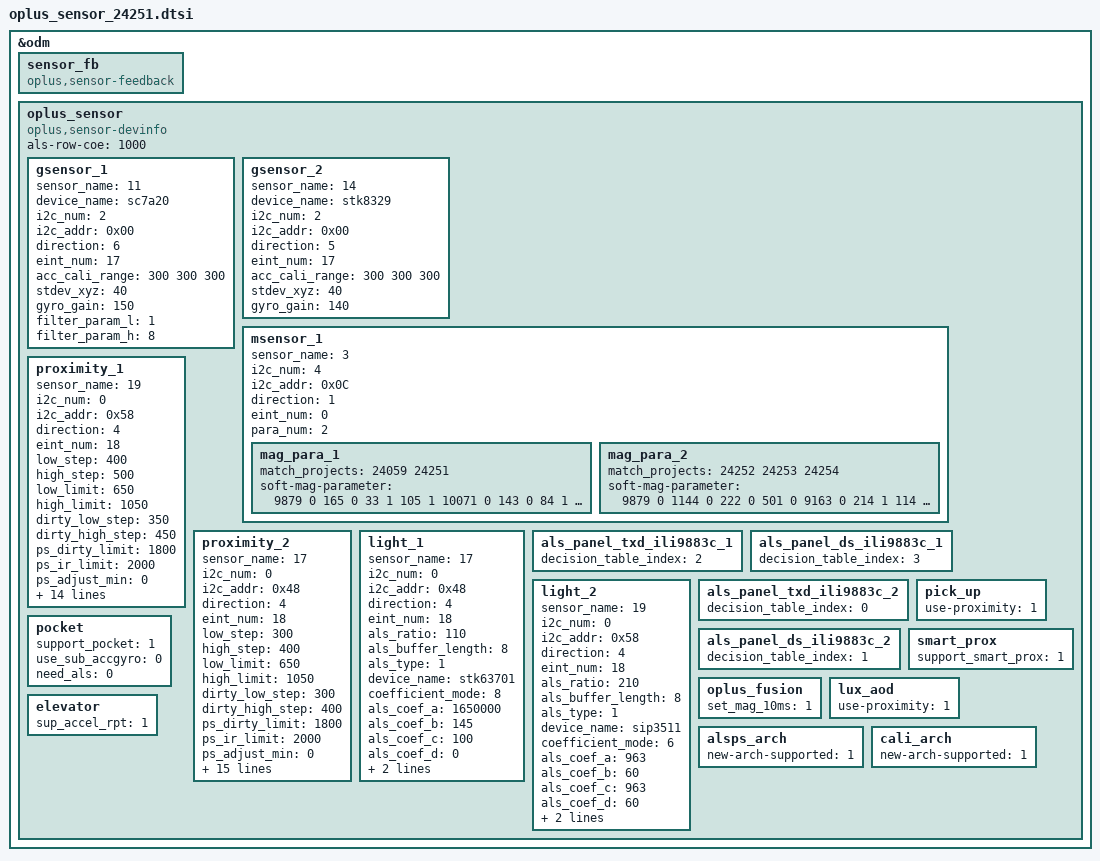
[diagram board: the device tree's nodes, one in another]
&odm {
	sensor_fb: sensor_fb {
		compatible = "oplus,sensor-feedback";
	};
	oplus_sensor:oplus_sensor {
		compatible = "oplus,sensor-devinfo";
		als-row-coe = <1000>;
		/* sensor start */
		/*
		enum {
			LIS3DH,
			LSM6DS3,
			BMI160,
			LIS2HH12,
			LSM6DSM,
			BMI2XY,
			LSM6DSO,
			ICM4X6XX,
			ICM4263X,
			ICM4N607,
			BMI22X,
			SC7A20,
			MC34X9,
			BMA4XY,
			STK8329,
			BMI3XY,
		};
		*/
		gsensor_1: gsensor_1 {
			status = "okay";
			sensor_name = <11>;//SC7A20
			device_name = "sc7a20";
			i2c_num = <2>;
			i2c_addr = <0x00>;
			direction = <6>;
			eint_num = <17>;
			acc_cali_range= <300 300 300>;
			stdev_xyz = <40>;
			gyro_gain = <150>;
			filter_param_l = <1>;
			filter_param_h = <8>;
		};
		gsensor_2: gsensor_2 {
			status = "okay";
			sensor_name = <14>;//STK8329
			device_name = "stk8329";
			i2c_num = <2>;
			i2c_addr = <0x00>;
			direction = <5>;
			eint_num = <17>;
			acc_cali_range= <300 300 300>;
			stdev_xyz = <40>;
			gyro_gain = <140>;
		};
		/*
		enum {
			AKM09911,
			MMC3530,
			MMC5603,
			MXG4300,
			AKM09918,
		};
		*/
		msensor_1: msensor_1 {
			status = "okay";
			sensor_name = <3>;//MXG4300
			i2c_num = <4>;
			i2c_addr = <0x0C>;
			direction = <1>;
			eint_num = <0>;
			para_num = <2>;
			mag_para_1 {
				match_projects = <24059 24251>;
				soft-mag-parameter = <9879 0 165 0 33 1 105 1 10071 0 143 0 84 1 102 1 10746 0>;
			};
			mag_para_2 {
				match_projects = <24252 24253 24254>;   // NFC
				soft-mag-parameter = <9879 0 1144 0 222 0 501 0 9163 0 214 1 114 1 236 1 10777 0>;
			};
		};
		/*
		enum {
			TMD2725,
			APSD9922,
			STK3335,
			STK3331,
			STK2232,
			TCS3701,
			STK32600,
			STK33502,
			MN78911,
			TCS3720,
			SIP3515,
			STK3329,
			LTR569,
			SIP3510,
		};
		*/
		proximity_1: proximity_1 {
			status = "okay";
			sensor_name = <19>; //SIP3511
			i2c_num = <0>;
			i2c_addr = <0x58>;
			direction = <4>;
			eint_num = <18>;
			low_step = <400>;
			high_step = <500>;
			low_limit = <650>;
			high_limit = <1050>;
			dirty_low_step = <350>;
			dirty_high_step = <450>;
			ps_dirty_limit = <1800>;
			ps_ir_limit = <2000>;
			ps_adjust_min = <0>;
			ps_adjust_max = <600>;
			sampling_count = <5>;
			step_max = <400>;
			step_min = <100>;
			step_div = <2000>;
			anti_shake_delta = <70>;
			dynamic_cali_max = <2000>;
			raw2offset_radio = <1000>;
			offset_max = <60000>;
			offset_range_min = <0>;
			offset_range_max = <65534>;
			force_cali_limit = <2000>;
			cali_jitter_limit = <20>;
			cal_offset_margin = <5000>;
		};
		proximity_2: proximity_2 {
			status = "okay";
			sensor_name = <17>; //stk63701
			i2c_num = <0>;
			i2c_addr = <0x48>;
			direction = <4>;
			eint_num = <18>;
			low_step = <300>;
			high_step = <400>;
			low_limit = <650>;
			high_limit = <1050>;
			dirty_low_step = <300>;
			dirty_high_step = <400>;
			ps_dirty_limit = <1800>;
			ps_ir_limit = <2000>;
			ps_adjust_min = <0>;
			ps_adjust_max = <1850>;
			sampling_count = <5>;
			step_max = <400>;
			step_min = <100>;
			step_div = <2000>;
			anti_shake_delta = <70>;
			dynamic_cali_max = <2000>;
			raw2offset_radio = <1000>;
			offset_max = <60000>;
			offset_range_min = <0>;
			offset_range_max = <65534>;
			force_cali_limit = <2000>;
			cali_jitter_limit = <20>;
			cal_offset_margin = <3000>;
			sensor-reg = <0x05 0x20>;
		};
		light_1: light_1 {
			status = "okay";
			sensor_name = <17>; //stk63701
			i2c_num = <0>;
			i2c_addr = <0x48>;
			direction = <4>;
			eint_num = <18>;
			als_ratio = <110>;
			als_buffer_length =<8>;
			als_type = <1>;//<1-normal;2-under screen;3-normal needed compensation>
			device_name = "stk63701";
			coefficient_mode = <8>;
			als_coef_a = <1650000>; //*100
			als_coef_b = <145>; //*100
			als_coef_c = <100>; //*100
			als_coef_d = <0>; //*100
			als_coef_e = <485>; //*100
			als_coef_ratio = <5000>;
		};
		als_panel_txd_ili9883c_1: als_panel_txd_ili9883c_1 {
			status = "okay";
			decision_table_index = <2>;
		};
		als_panel_ds_ili9883c_1: als_panel_ds_ili9883c_1 {
			status = "okay";
			decision_table_index = <3>;
		};
		light_2: light_2 {
			status = "okay";
			sensor_name = <19>; //SIP3511
			i2c_num = <0>;
			i2c_addr = <0x58>;
			direction = <4>;
			eint_num = <18>;
			als_ratio = <210>;
			als_buffer_length =<8>;
			als_type = <1>;//<1-normal;2-under screen;3-normal needed compensation>
			device_name = "sip3511";
			coefficient_mode = <6>;
			als_coef_a = <963>; //*100
			als_coef_b = <60>; //*100
			als_coef_c = <963>; //*100
			als_coef_d = <60>; //*100
			als_coef_e = <2490>; //*100
			als_coef_ratio = <1500>;
		};
		als_panel_txd_ili9883c_2: als_panel_txd_ili9883c_2 {
			status = "okay";
			decision_table_index = <0>;
		};
		als_panel_ds_ili9883c_2: als_panel_ds_ili9883c_2 {
			status = "okay";
			decision_table_index = <1>;
		};
		pick_up: pick_up {
			status = "okay";
			use-proximity = <1>;
		};
		pocket: pocket {
			status = "okay";
			support_pocket = <1>;
			use_sub_accgyro = <0>;
			need_als = <0>;
		};
		smart_prox: smart_prox {
			status = "okay";
			support_smart_prox = <1>;
		};
		oplus_fusion: oplus_fusion {
			status = "okay";
			set_mag_10ms = <1>;
		};
		lux_aod: lux_aod {
			status = "okay";
			use-proximity = <1>;
		};
		alsps_arch: alsps_arch {
			status = "okay";
			new-arch-supported = <1>;
		};
		cali_arch: cali_arch {
			status = "okay";
			new-arch-supported = <1>;
		};
		elevator: elevator{
			status = "okay";
			sup_accel_rpt = <1>;
		};
	};
/* sensor end */
};
